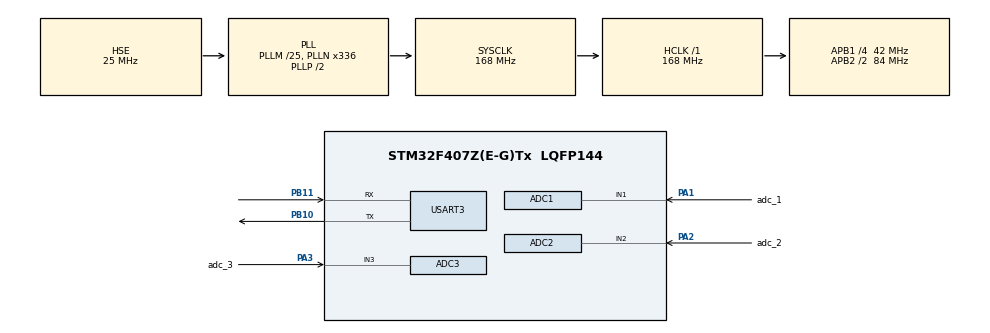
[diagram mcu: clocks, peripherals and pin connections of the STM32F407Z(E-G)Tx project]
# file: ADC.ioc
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ADC1.Channel-2\#ChannelRegularConversion=ADC_CHANNEL_1
ADC1.Channel-3\#ChannelRegularConversion=ADC_CHANNEL_1
ADC1.Channel-4\#ChannelRegularConversion=ADC_CHANNEL_1
ADC1.ClockPrescaler=ADC_CLOCK_SYNC_PCLK_DIV4
ADC1.DiscontinuousConvMode=ENABLE
ADC1.InjNumberOfConversion=0
ADC1.NbrOfConversion=3
ADC1.NbrOfConversionFlag=1
ADC1.Rank-2\#ChannelRegularConversion=1
ADC1.Rank-3\#ChannelRegularConversion=2
ADC1.Rank-4\#ChannelRegularConversion=3
ADC1.SamplingTime-2\#ChannelRegularConversion=ADC_SAMPLETIME_3CYCLES
ADC1.SamplingTime-3\#ChannelRegularConversion=ADC_SAMPLETIME_3CYCLES
ADC1.SamplingTime-4\#ChannelRegularConversion=ADC_SAMPLETIME_3CYCLES
ADC1.ScanConvMode=ENABLE
ADC1.master=1
ADC2.Channel-0\#ChannelRegularConversion=ADC_CHANNEL_2
ADC2.Channel-1\#ChannelRegularConversion=ADC_CHANNEL_2
ADC2.Channel-2\#ChannelRegularConversion=ADC_CHANNEL_2
ADC2.ClockPrescaler=ADC_CLOCK_SYNC_PCLK_DIV4
ADC2.NbrOfConversion=3
ADC2.NbrOfConversionFlag=1
ADC2.Rank-0\#ChannelRegularConversion=1
ADC2.Rank-1\#ChannelRegularConversion=2
ADC2.Rank-2\#ChannelRegularConversion=3
ADC2.SamplingTime-0\#ChannelRegularConversion=ADC_SAMPLETIME_3CYCLES
ADC2.SamplingTime-1\#ChannelRegularConversion=ADC_SAMPLETIME_3CYCLES
ADC2.SamplingTime-2\#ChannelRegularConversion=ADC_SAMPLETIME_3CYCLES
ADC3.Channel-0\#ChannelRegularConversion=ADC_CHANNEL_3
ADC3.Channel-1\#ChannelRegularConversion=ADC_CHANNEL_3
ADC3.Channel-2\#ChannelRegularConversion=ADC_CHANNEL_3
ADC3.ClockPrescaler=ADC_CLOCK_SYNC_PCLK_DIV4
ADC3.NbrOfConversion=3
ADC3.NbrOfConversionFlag=1
ADC3.Rank-0\#ChannelRegularConversion=1
ADC3.Rank-1\#ChannelRegularConversion=2
ADC3.Rank-2\#ChannelRegularConversion=3
ADC3.SamplingTime-0\#ChannelRegularConversion=ADC_SAMPLETIME_3CYCLES
ADC3.SamplingTime-1\#ChannelRegularConversion=ADC_SAMPLETIME_3CYCLES
ADC3.SamplingTime-2\#ChannelRegularConversion=ADC_SAMPLETIME_3CYCLES
Mcu.Family=STM32F4
Mcu.Name=STM32F407Z(E-G)Tx
Mcu.Package=LQFP144
NVIC.PriorityGroup=NVIC_PRIORITYGROUP_4
PA1.GPIO_Label=adc_1
PA1.Signal=ADCx_IN1
PA13.Mode=Serial_Wire
PA13.Signal=SYS_JTMS-SWDIO
PA14.Mode=Serial_Wire
PA14.Signal=SYS_JTCK-SWCLK
PA2.GPIO_Label=adc_2
PA2.Signal=ADCx_IN2
PA3.GPIO_Label=adc_3
PA3.Signal=ADCx_IN3
PB10.Mode=Asynchronous
PB10.Signal=USART3_TX
PB11.Mode=Asynchronous
PB11.Signal=USART3_RX
PC14-OSC32_IN.Mode=LSE-External-Oscillator
PC14-OSC32_IN.Signal=RCC_OSC32_IN
PC15-OSC32_OUT.Mode=LSE-External-Oscillator
PC15-OSC32_OUT.Signal=RCC_OSC32_OUT
PH0-OSC_IN.Mode=HSE-External-Oscillator
PH0-OSC_IN.Signal=RCC_OSC_IN
PH1-OSC_OUT.Mode=HSE-External-Oscillator
PH1-OSC_OUT.Signal=RCC_OSC_OUT
ProjectManager.HeapSize=0x200
ProjectManager.StackSize=0x400
ProjectManager.TargetToolchain=MDK-ARM V5.32
RCC.48MHZClocksFreq_Value=84000000
RCC.AHBFreq_Value=168000000
RCC.APB1CLKDivider=RCC_HCLK_DIV4
RCC.APB1Freq_Value=42000000
RCC.APB1TimFreq_Value=84000000
RCC.APB2CLKDivider=RCC_HCLK_DIV2
RCC.APB2Freq_Value=84000000
RCC.APB2TimFreq_Value=168000000
RCC.CortexFreq_Value=168000000
RCC.HCLKFreq_Value=168000000
RCC.HSE_VALUE=25000000
RCC.HSI_VALUE=16000000
RCC.PLLM=25
RCC.PLLN=336
RCC.PLLSourceVirtual=RCC_PLLSOURCE_HSE
RCC.SYSCLKFreq_VALUE=168000000
RCC.SYSCLKSource=RCC_SYSCLKSOURCE_PLLCLK
RCC.VCOOutputFreq_Value=336000000
SH.ADCx_IN1.0=ADC1_IN1,IN1
SH.ADCx_IN2.0=ADC2_IN2,IN2
SH.ADCx_IN3.0=ADC3_IN3,IN3
USART3.VirtualMode=VM_ASYNC
board=custom

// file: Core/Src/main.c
/* USER CODE BEGIN Header */
/**
  ******************************************************************************
  * @file           : main.c
  * @brief          : Main program body
  ******************************************************************************
  * @attention
  *
  * Copyright (c) 2026 STMicroelectronics.
  * All rights reserved.
  *
  * This software is licensed under terms that can be found in the LICENSE file
  * in the root directory of this software component.
  * If no LICENSE file comes with this software, it is provided AS-IS.
  *
  ******************************************************************************
  */
/* USER CODE END Header */
#include "main.h"
#include "adc.h"
#include "usart.h"
#include "gpio.h"

/* USER CODE BEGIN Includes */

#include <stdio.h>
#include <string.h>

/* USER CODE END Includes */

/* USER CODE BEGIN PV */

uint32_t adc_val = 0;
float voltage = 0.0f;

/* USER CODE END PV */

void SystemClock_Config(void);

int main(void)
{

  /* MCU Configuration--------------------------------------------------------*/

  /* Reset of all peripherals, Initializes the Flash interface and the Systick. */
  HAL_Init();

  /* Configure the system clock */
  SystemClock_Config();

  /* Initialize all configured peripherals */
  MX_GPIO_Init();
  MX_ADC1_Init();
  MX_USART3_UART_Init();
  MX_ADC2_Init();
  MX_ADC3_Init();

  /* Infinite loop */
  /* USER CODE BEGIN WHILE */
  while (1)
  {
		HAL_ADC_Start(&hadc1);
		if((HAL_ADC_PollForConversion(&hadc1, 50)) == HAL_OK)
		{
			adc_val = HAL_ADC_GetValue(&hadc1);

			voltage = (float)adc_val / 4095 * 3.3f;

			printf("ADC的原始值：%d, ADC的转换值：%.3f V\r\n", adc_val, voltage);

		}

		HAL_Delay(500);

    /* USER CODE END WHILE */

  }
}

void SystemClock_Config(void)
{
  RCC_OscInitTypeDef RCC_OscInitStruct = {0};
  RCC_ClkInitTypeDef RCC_ClkInitStruct = {0};

  /** Configure the main internal regulator output voltage
  */
  __HAL_RCC_PWR_CLK_ENABLE();
  __HAL_PWR_VOLTAGESCALING_CONFIG(PWR_REGULATOR_VOLTAGE_SCALE1);

  /** Initializes the RCC Oscillators according to the specified parameters
  * in the RCC_OscInitTypeDef structure.
  */
  RCC_OscInitStruct.OscillatorType = RCC_OSCILLATORTYPE_HSE;
  RCC_OscInitStruct.HSEState = RCC_HSE_ON;
  RCC_OscInitStruct.PLL.PLLState = RCC_PLL_ON;
  RCC_OscInitStruct.PLL.PLLSource = RCC_PLLSOURCE_HSE;
  RCC_OscInitStruct.PLL.PLLM = 25;
  RCC_OscInitStruct.PLL.PLLN = 336;
  RCC_OscInitStruct.PLL.PLLP = RCC_PLLP_DIV2;
  RCC_OscInitStruct.PLL.PLLQ = 4;
  if (HAL_RCC_OscConfig(&RCC_OscInitStruct) != HAL_OK)
  {
    Error_Handler();
  }

  /** Initializes the CPU, AHB and APB buses clocks
  */
  RCC_ClkInitStruct.ClockType = RCC_CLOCKTYPE_HCLK|RCC_CLOCKTYPE_SYSCLK
                              |RCC_CLOCKTYPE_PCLK1|RCC_CLOCKTYPE_PCLK2;
  RCC_ClkInitStruct.SYSCLKSource = RCC_SYSCLKSOURCE_PLLCLK;
  RCC_ClkInitStruct.AHBCLKDivider = RCC_SYSCLK_DIV1;
  RCC_ClkInitStruct.APB1CLKDivider = RCC_HCLK_DIV4;
  RCC_ClkInitStruct.APB2CLKDivider = RCC_HCLK_DIV2;

  if (HAL_RCC_ClockConfig(&RCC_ClkInitStruct, FLASH_LATENCY_5) != HAL_OK)
  {
    Error_Handler();
  }
}

/* USER CODE BEGIN 4 */

int fputc(int ch, FILE *f)
{
    // 这里的huart1要改成你实际用的串口句柄
    HAL_UART_Transmit(&huart3, (uint8_t *)&ch, 1, 100);
    return ch;  // 必须有返回值！之前的警告就是这里导致的
}

/* USER CODE END 4 */

void Error_Handler(void)
{
  __disable_irq();
  while (1)
  {
  }
}
